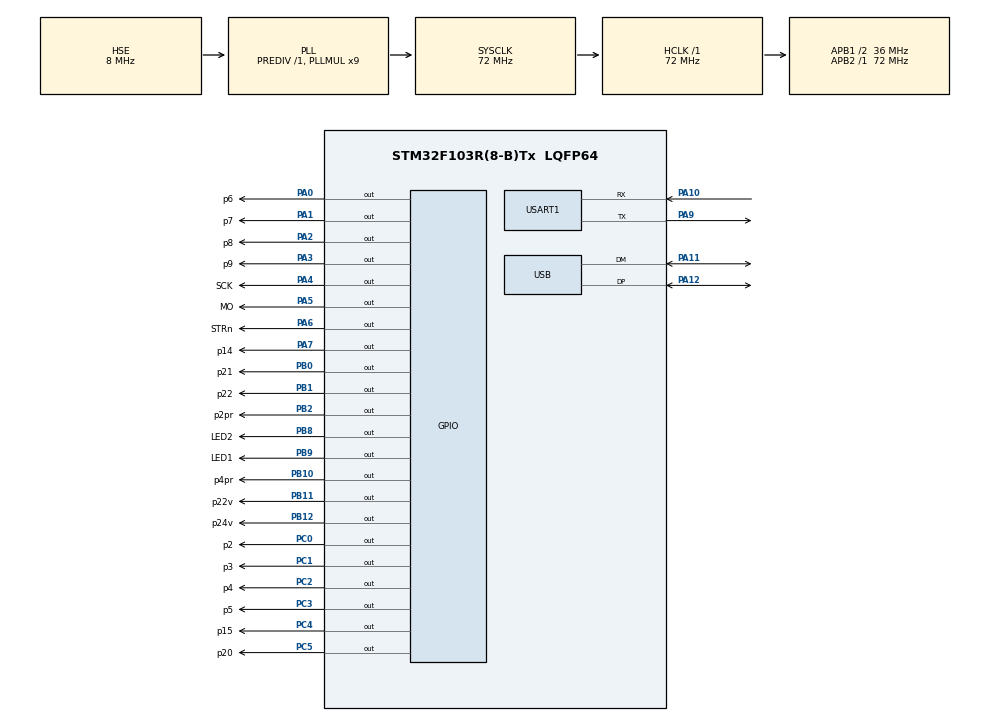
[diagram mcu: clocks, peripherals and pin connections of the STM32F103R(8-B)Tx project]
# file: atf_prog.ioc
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FREERTOS.INCLUDE_vTaskDelete=0
FREERTOS.Tasks01=Prog,0,128,StartProg,Default,NULL,Dynamic,NULL,NULL;LED,-3,128,StartLED,Default,NULL,Dynamic,NULL,NULL
Mcu.Family=STM32F1
Mcu.Name=STM32F103R(8-B)Tx
Mcu.Package=LQFP64
NVIC.PriorityGroup=NVIC_PRIORITYGROUP_4
NVIC.RCC_IRQn=true\:5\:0\:false\:true\:true\:2\:true\:true
NVIC.TIM1_UP_IRQn=true\:0\:0\:false\:false\:true\:false\:false
NVIC.TimeBase=TIM1_UP_IRQn
NVIC.TimeBaseIP=TIM1
NVIC.USART1_IRQn=true\:5\:0\:false\:true\:true\:1\:true\:true
NVIC.USB_LP_CAN1_RX0_IRQn=true\:5\:0\:false\:false\:true\:true\:false
PA0-WKUP.GPIO_Label=p6
PA0-WKUP.GPIO_ModeDefaultOutputPP=GPIO_MODE_OUTPUT_OD
PA0-WKUP.GPIO_Speed=GPIO_SPEED_FREQ_LOW
PA0-WKUP.PinState=GPIO_PIN_SET
PA0-WKUP.Signal=GPIO_Output
PA1.GPIO_Label=p7
PA1.GPIO_ModeDefaultOutputPP=GPIO_MODE_OUTPUT_OD
PA1.GPIO_Speed=GPIO_SPEED_FREQ_LOW
PA1.PinState=GPIO_PIN_SET
PA1.Signal=GPIO_Output
PA10.Mode=Asynchronous
PA10.Signal=USART1_RX
PA11.Mode=Device
PA11.Signal=USB_DM
PA12.Mode=Device
PA12.Signal=USB_DP
PA13.Mode=Serial_Wire
PA13.Signal=SYS_JTMS-SWDIO
PA14.Mode=Serial_Wire
PA14.Signal=SYS_JTCK-SWCLK
PA2.GPIO_Label=p8
PA2.GPIO_ModeDefaultOutputPP=GPIO_MODE_OUTPUT_OD
PA2.GPIO_Speed=GPIO_SPEED_FREQ_LOW
PA2.PinState=GPIO_PIN_SET
PA2.Signal=GPIO_Output
PA3.GPIO_Label=p9
PA3.GPIO_ModeDefaultOutputPP=GPIO_MODE_OUTPUT_OD
PA3.GPIO_Speed=GPIO_SPEED_FREQ_LOW
PA3.PinState=GPIO_PIN_SET
PA3.Signal=GPIO_Output
PA4.GPIO_Label=SCK
PA4.GPIO_ModeDefaultOutputPP=GPIO_MODE_OUTPUT_OD
PA4.GPIO_Speed=GPIO_SPEED_FREQ_LOW
PA4.PinState=GPIO_PIN_SET
PA4.Signal=GPIO_Output
PA5.GPIO_Label=MO
PA5.GPIO_ModeDefaultOutputPP=GPIO_MODE_OUTPUT_OD
PA5.GPIO_Speed=GPIO_SPEED_FREQ_LOW
PA5.PinState=GPIO_PIN_SET
PA5.Signal=GPIO_Output
PA6.GPIO_Label=STRn
PA6.GPIO_ModeDefaultOutputPP=GPIO_MODE_OUTPUT_OD
PA6.GPIO_Speed=GPIO_SPEED_FREQ_LOW
PA6.PinState=GPIO_PIN_SET
PA6.Signal=GPIO_Output
PA7.GPIO_Label=p14
PA7.GPIO_ModeDefaultOutputPP=GPIO_MODE_OUTPUT_OD
PA7.GPIO_Speed=GPIO_SPEED_FREQ_LOW
PA7.PinState=GPIO_PIN_SET
PA7.Signal=GPIO_Output
PA9.Mode=Asynchronous
PA9.Signal=USART1_TX
PB0.GPIO_Label=p21
PB0.GPIO_ModeDefaultOutputPP=GPIO_MODE_OUTPUT_OD
PB0.GPIO_Speed=GPIO_SPEED_FREQ_LOW
PB0.PinState=GPIO_PIN_SET
PB0.Signal=GPIO_Output
PB1.GPIO_Label=p22
PB1.GPIO_ModeDefaultOutputPP=GPIO_MODE_OUTPUT_OD
PB1.GPIO_Speed=GPIO_SPEED_FREQ_LOW
PB1.PinState=GPIO_PIN_SET
PB1.Signal=GPIO_Output
PB10.GPIO_Label=p4pr
PB10.Signal=GPIO_Output
PB11.GPIO_Label=p22v
PB11.Signal=GPIO_Output
PB12.GPIO_Label=p24v
PB12.Signal=GPIO_Output
PB2.GPIO_Label=p2pr
PB2.Signal=GPIO_Output
PB8.GPIO_Label=LED2
PB8.Signal=GPIO_Output
PB9.GPIO_Label=LED1
PB9.Signal=GPIO_Output
PC0.GPIO_Label=p2
PC0.GPIO_ModeDefaultOutputPP=GPIO_MODE_OUTPUT_OD
PC0.GPIO_Speed=GPIO_SPEED_FREQ_LOW
PC0.PinState=GPIO_PIN_SET
PC0.Signal=GPIO_Output
PC1.GPIO_Label=p3
PC1.GPIO_ModeDefaultOutputPP=GPIO_MODE_OUTPUT_OD
PC1.GPIO_Speed=GPIO_SPEED_FREQ_LOW
PC1.PinState=GPIO_PIN_SET
PC1.Signal=GPIO_Output
PC14-OSC32_IN.Mode=LSE-External-Oscillator
PC14-OSC32_IN.Signal=RCC_OSC32_IN
PC15-OSC32_OUT.Mode=LSE-External-Oscillator
PC15-OSC32_OUT.Signal=RCC_OSC32_OUT
PC2.GPIO_Label=p4
PC2.GPIO_ModeDefaultOutputPP=GPIO_MODE_OUTPUT_OD
PC2.GPIO_Speed=GPIO_SPEED_FREQ_LOW
PC2.PinState=GPIO_PIN_SET
PC2.Signal=GPIO_Output
PC3.GPIO_Label=p5
PC3.GPIO_ModeDefaultOutputPP=GPIO_MODE_OUTPUT_OD
PC3.GPIO_Speed=GPIO_SPEED_FREQ_LOW
PC3.PinState=GPIO_PIN_SET
PC3.Signal=GPIO_Output
PC4.GPIO_Label=p15
PC4.GPIO_ModeDefaultOutputPP=GPIO_MODE_OUTPUT_OD
PC4.GPIO_Speed=GPIO_SPEED_FREQ_LOW
PC4.PinState=GPIO_PIN_SET
PC4.Signal=GPIO_Output
PC5.GPIO_Label=p20
PC5.GPIO_ModeDefaultOutputPP=GPIO_MODE_OUTPUT_OD
PC5.GPIO_Speed=GPIO_SPEED_FREQ_LOW
PC5.PinState=GPIO_PIN_SET
PC5.Signal=GPIO_Output
PD0-OSC_IN.Mode=HSE-External-Oscillator
PD0-OSC_IN.Signal=RCC_OSC_IN
PD1-OSC_OUT.Mode=HSE-External-Oscillator
PD1-OSC_OUT.Signal=RCC_OSC_OUT
ProjectManager.HeapSize=0x200
ProjectManager.StackSize=0x400
ProjectManager.TargetToolchain=MDK-ARM V5
RCC.AHBFreq_Value=72000000
RCC.APB1CLKDivider=RCC_HCLK_DIV2
RCC.APB1Freq_Value=36000000
RCC.APB1TimFreq_Value=72000000
RCC.APB2Freq_Value=72000000
RCC.APB2TimFreq_Value=72000000
RCC.EnbaleCSS=true
RCC.HCLKFreq_Value=72000000
RCC.PLLMUL=RCC_PLL_MUL9
RCC.SYSCLKFreq_VALUE=72000000
RCC.SYSCLKSource=RCC_SYSCLKSOURCE_PLLCLK
RCC.USBFreq_Value=48000000
RCC.USBPrescaler=RCC_USBCLKSOURCE_PLL_DIV1_5
USART1.VirtualMode=VM_ASYNC
USB.ep0_mps=DEP0CTL_MPS_64
USB_DEVICE.CLASS_NAME_FS=CUSTOMHID
USB_DEVICE.CONFIGURATION_STRING_CUSTOMHID_FS=ATFP HID Config
USB_DEVICE.INTERFACE_STRING_CUSTOMHID_FS=ATFP HID Interface
USB_DEVICE.MANUFACTURER_STRING=andreil
USB_DEVICE.PID_CUSTOMHID_FS=7346
USB_DEVICE.PRODUCT_STRING_CUSTOMHID_FS=ATF Prog
USB_DEVICE.SERIALNUMBER_STRING_CUSTOMHID_FS=000000000057
USB_DEVICE.USBD_CUSTOMHID_OUTREPORT_BUF_SIZE=32
USB_DEVICE.USBD_CUSTOM_HID_REPORT_DESC_SIZE=32
USB_DEVICE.USBD_DEBUG_LEVEL=3
USB_DEVICE.VirtualMode=CustomHid
USB_DEVICE.VirtualModeFS=Custom_Hid_FS
VP_FREERTOS_VS_ENABLE.Mode=Enabled
VP_IWDG_VS_IWDG.Mode=IWDG_Activate
VP_SYS_VS_tim1.Mode=TIM1
VP_USB_DEVICE_VS_USB_DEVICE_CUSTOM_HID_FS.Mode=CUSTOM_HID_FS
board=atf_prog

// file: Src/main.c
/**
  ******************************************************************************
  * @file           : main.c
  * @brief          : Main program body
  ******************************************************************************
  * This notice applies to any and all portions of this file
  * that are not between comment pairs USER CODE BEGIN and
  * USER CODE END. Other portions of this file, whether
  * inserted by the user or by software development tools
  * are owned by their respective copyright owners.
  *
  * Copyright (c) 2018 STMicroelectronics International N.V.
  * All rights reserved.
  *
  * Redistribution and use in source and binary forms, with or without
  * modification, are permitted, provided that the following conditions are met:
  *
  * 1. Redistribution of source code must retain the above copyright notice,
  *    this list of conditions and the following disclaimer.
  * 2. Redistributions in binary form must reproduce the above copyright notice,
  *    this list of conditions and the following disclaimer in the documentation
  *    and/or other materials provided with the distribution.
  * 3. Neither the name of STMicroelectronics nor the names of other
  *    contributors to this software may be used to endorse or promote products
  *    derived from this software without specific written permission.
  * 4. This software, including modifications and/or derivative works of this
  *    software, must execute solely and exclusively on microcontroller or
  *    microprocessor devices manufactured by or for STMicroelectronics.
  * 5. Redistribution and use of this software other than as permitted under
  *    this license is void and will automatically terminate your rights under
  *    this license.
  *
  * THIS SOFTWARE IS PROVIDED BY STMICROELECTRONICS AND CONTRIBUTORS "AS IS"
  * AND ANY EXPRESS, IMPLIED OR STATUTORY WARRANTIES, INCLUDING, BUT NOT
  * LIMITED TO, THE IMPLIED WARRANTIES OF MERCHANTABILITY, FITNESS FOR A
  * PARTICULAR PURPOSE AND NON-INFRINGEMENT OF THIRD PARTY INTELLECTUAL PROPERTY
  * RIGHTS ARE DISCLAIMED TO THE FULLEST EXTENT PERMITTED BY LAW. IN NO EVENT
  * SHALL STMICROELECTRONICS OR CONTRIBUTORS BE LIABLE FOR ANY DIRECT, INDIRECT,
  * INCIDENTAL, SPECIAL, EXEMPLARY, OR CONSEQUENTIAL DAMAGES (INCLUDING, BUT NOT
  * LIMITED TO, PROCUREMENT OF SUBSTITUTE GOODS OR SERVICES; LOSS OF USE, DATA,
  * OR PROFITS; OR BUSINESS INTERRUPTION) HOWEVER CAUSED AND ON ANY THEORY OF
  * LIABILITY, WHETHER IN CONTRACT, STRICT LIABILITY, OR TORT (INCLUDING
  * NEGLIGENCE OR OTHERWISE) ARISING IN ANY WAY OUT OF THE USE OF THIS SOFTWARE,
  * EVEN IF ADVISED OF THE POSSIBILITY OF SUCH DAMAGE.
  *
  ******************************************************************************
  */
#include "main.h"
#include "stm32f1xx_hal.h"
#include "cmsis_os.h"
#include "usb_device.h"

/* USER CODE BEGIN Includes */
#include "gal_prog.h"
/* USER CODE END Includes */

IWDG_HandleTypeDef hiwdg;

UART_HandleTypeDef huart1;

osThreadId ProgHandle;
osThreadId LEDHandle;

/* USER CODE BEGIN PV */
/* Private variables ---------------------------------------------------------*/
GALProg_t prog;
/* USER CODE END PV */

void SystemClock_Config(void);
static void MX_GPIO_Init(void);
static void MX_IWDG_Init(void);
static void MX_USART1_UART_Init(void);
void StartProg(void const * argument);
void StartLED(void const * argument);
static void MX_NVIC_Init(void);

/* USER CODE BEGIN PFP */
/* Private function prototypes -----------------------------------------------*/

/* USER CODE END PFP */

/* USER CODE BEGIN 0 */

int fputc(int ch, FILE *f)
{
  /* Place your implementation of fputc here */
  /* e.g. write a character to the USART1 and Loop until the end of transmission */
  HAL_UART_Transmit(&huart1, (uint8_t *)&ch, 1, 0xFFFF);

  return ch;
}

/* USER CODE END 0 */

int main(void)
{

  /* MCU Configuration----------------------------------------------------------*/

  /* Reset of all peripherals, Initializes the Flash interface and the Systick. */
  HAL_Init();

  /* Configure the system clock */
  SystemClock_Config();

  /* Initialize all configured peripherals */
  MX_GPIO_Init();
  MX_IWDG_Init();
  MX_USART1_UART_Init();

  /* Initialize interrupts */
  MX_NVIC_Init();
  /* USER CODE BEGIN 2 */

	printf("ATF Programmer\n\r");

  /* USER CODE END 2 */

  /* Create the thread(s) */
  /* definition and creation of Prog */
  osThreadDef(Prog, StartProg, osPriorityNormal, 0, 128);
  ProgHandle = osThreadCreate(osThread(Prog), NULL);

  /* definition and creation of LED */
  osThreadDef(LED, StartLED, osPriorityIdle, 0, 128);
  LEDHandle = osThreadCreate(osThread(LED), NULL);

  /* Start scheduler */
  osKernelStart();

  /* We should never get here as control is now taken by the scheduler */

  /* Infinite loop */
  while (1)
  {

  }

}

void SystemClock_Config(void)
{

  RCC_OscInitTypeDef RCC_OscInitStruct;
  RCC_ClkInitTypeDef RCC_ClkInitStruct;
  RCC_PeriphCLKInitTypeDef PeriphClkInit;

    /**Initializes the CPU, AHB and APB busses clocks
    */
  RCC_OscInitStruct.OscillatorType = RCC_OSCILLATORTYPE_LSI|RCC_OSCILLATORTYPE_HSE;
  RCC_OscInitStruct.HSEState = RCC_HSE_ON;
  RCC_OscInitStruct.HSEPredivValue = RCC_HSE_PREDIV_DIV1;
  RCC_OscInitStruct.HSIState = RCC_HSI_ON;
  RCC_OscInitStruct.LSIState = RCC_LSI_ON;
  RCC_OscInitStruct.PLL.PLLState = RCC_PLL_ON;
  RCC_OscInitStruct.PLL.PLLSource = RCC_PLLSOURCE_HSE;
  RCC_OscInitStruct.PLL.PLLMUL = RCC_PLL_MUL9;
  if (HAL_RCC_OscConfig(&RCC_OscInitStruct) != HAL_OK)
  {
    _Error_Handler(__FILE__, __LINE__);
  }

    /**Initializes the CPU, AHB and APB busses clocks
    */
  RCC_ClkInitStruct.ClockType = RCC_CLOCKTYPE_HCLK|RCC_CLOCKTYPE_SYSCLK
                              |RCC_CLOCKTYPE_PCLK1|RCC_CLOCKTYPE_PCLK2;
  RCC_ClkInitStruct.SYSCLKSource = RCC_SYSCLKSOURCE_PLLCLK;
  RCC_ClkInitStruct.AHBCLKDivider = RCC_SYSCLK_DIV1;
  RCC_ClkInitStruct.APB1CLKDivider = RCC_HCLK_DIV2;
  RCC_ClkInitStruct.APB2CLKDivider = RCC_HCLK_DIV1;

  if (HAL_RCC_ClockConfig(&RCC_ClkInitStruct, FLASH_LATENCY_2) != HAL_OK)
  {
    _Error_Handler(__FILE__, __LINE__);
  }

  PeriphClkInit.PeriphClockSelection = RCC_PERIPHCLK_USB;
  PeriphClkInit.UsbClockSelection = RCC_USBCLKSOURCE_PLL_DIV1_5;
  if (HAL_RCCEx_PeriphCLKConfig(&PeriphClkInit) != HAL_OK)
  {
    _Error_Handler(__FILE__, __LINE__);
  }

    /**Enables the Clock Security System
    */
  HAL_RCC_EnableCSS();

    /**Configure the Systick interrupt time
    */
  HAL_SYSTICK_Config(HAL_RCC_GetHCLKFreq()/1000);

    /**Configure the Systick
    */
  HAL_SYSTICK_CLKSourceConfig(SYSTICK_CLKSOURCE_HCLK);

  /* SysTick_IRQn interrupt configuration */
  HAL_NVIC_SetPriority(SysTick_IRQn, 15, 0);
}

/**
  * @brief NVIC Configuration.
  * @retval None
  */
static void MX_NVIC_Init(void)
{
  /* USART1_IRQn interrupt configuration */
  HAL_NVIC_SetPriority(USART1_IRQn, 5, 0);
  HAL_NVIC_EnableIRQ(USART1_IRQn);
  /* RCC_IRQn interrupt configuration */
  HAL_NVIC_SetPriority(RCC_IRQn, 5, 0);
  HAL_NVIC_EnableIRQ(RCC_IRQn);
}

/* IWDG init function */
static void MX_IWDG_Init(void)
{

  hiwdg.Instance = IWDG;
  hiwdg.Init.Prescaler = IWDG_PRESCALER_4;
  hiwdg.Init.Reload = 4095;
  if (HAL_IWDG_Init(&hiwdg) != HAL_OK)
  {
    _Error_Handler(__FILE__, __LINE__);
  }

}

/* USART1 init function */
static void MX_USART1_UART_Init(void)
{

  huart1.Instance = USART1;
  huart1.Init.BaudRate = 115200;
  huart1.Init.WordLength = UART_WORDLENGTH_8B;
  huart1.Init.StopBits = UART_STOPBITS_1;
  huart1.Init.Parity = UART_PARITY_NONE;
  huart1.Init.Mode = UART_MODE_TX_RX;
  huart1.Init.HwFlowCtl = UART_HWCONTROL_NONE;
  huart1.Init.OverSampling = UART_OVERSAMPLING_16;
  if (HAL_UART_Init(&huart1) != HAL_OK)
  {
    _Error_Handler(__FILE__, __LINE__);
  }

}

/** Configure pins as
        * Analog
        * Input
        * Output
        * EVENT_OUT
        * EXTI
        * Free pins are configured automatically as Analog (this feature is enabled through
        * the Code Generation settings)
*/
static void MX_GPIO_Init(void)
{

  GPIO_InitTypeDef GPIO_InitStruct;

  /* GPIO Ports Clock Enable */
  __HAL_RCC_GPIOC_CLK_ENABLE();
  __HAL_RCC_GPIOD_CLK_ENABLE();
  __HAL_RCC_GPIOA_CLK_ENABLE();
  __HAL_RCC_GPIOB_CLK_ENABLE();

  /*Configure GPIO pin Output Level */
  HAL_GPIO_WritePin(GPIOC, p2_Pin|p3_Pin|p4_Pin|p5_Pin
                          |p15_Pin|p20_Pin, GPIO_PIN_SET);

  /*Configure GPIO pin Output Level */
  HAL_GPIO_WritePin(GPIOA, p6_Pin|p7_Pin|p8_Pin|p9_Pin
                          |SCK_Pin|MO_Pin|STRn_Pin|p14_Pin, GPIO_PIN_SET);

  /*Configure GPIO pin Output Level */
  HAL_GPIO_WritePin(GPIOB, p21_Pin|p22_Pin, GPIO_PIN_SET);

  /*Configure GPIO pin Output Level */
  HAL_GPIO_WritePin(GPIOB, p2pr_Pin|p4pr_Pin|p22v_Pin|p24v_Pin
                          |LED2_Pin|LED1_Pin, GPIO_PIN_RESET);

  /*Configure GPIO pins : PC13 PC6 PC7 PC8
                           PC9 PC10 PC11 PC12 */
  GPIO_InitStruct.Pin = GPIO_PIN_13|GPIO_PIN_6|GPIO_PIN_7|GPIO_PIN_8
                          |GPIO_PIN_9|GPIO_PIN_10|GPIO_PIN_11|GPIO_PIN_12;
  GPIO_InitStruct.Mode = GPIO_MODE_ANALOG;
  HAL_GPIO_Init(GPIOC, &GPIO_InitStruct);

  /*Configure GPIO pins : p2_Pin p3_Pin p4_Pin p5_Pin
                           p15_Pin p20_Pin */
  GPIO_InitStruct.Pin = p2_Pin|p3_Pin|p4_Pin|p5_Pin
                          |p15_Pin|p20_Pin;
  GPIO_InitStruct.Mode = GPIO_MODE_OUTPUT_OD;
  GPIO_InitStruct.Speed = GPIO_SPEED_FREQ_LOW;
  HAL_GPIO_Init(GPIOC, &GPIO_InitStruct);

  /*Configure GPIO pins : p6_Pin p7_Pin p8_Pin p9_Pin
                           SCK_Pin MO_Pin STRn_Pin p14_Pin */
  GPIO_InitStruct.Pin = p6_Pin|p7_Pin|p8_Pin|p9_Pin
                          |SCK_Pin|MO_Pin|STRn_Pin|p14_Pin;
  GPIO_InitStruct.Mode = GPIO_MODE_OUTPUT_OD;
  GPIO_InitStruct.Speed = GPIO_SPEED_FREQ_LOW;
  HAL_GPIO_Init(GPIOA, &GPIO_InitStruct);

  /*Configure GPIO pins : p21_Pin p22_Pin */
  GPIO_InitStruct.Pin = p21_Pin|p22_Pin;
  GPIO_InitStruct.Mode = GPIO_MODE_OUTPUT_OD;
  GPIO_InitStruct.Speed = GPIO_SPEED_FREQ_LOW;
  HAL_GPIO_Init(GPIOB, &GPIO_InitStruct);

  /*Configure GPIO pins : p2pr_Pin p4pr_Pin p22v_Pin p24v_Pin
                           LED2_Pin LED1_Pin */
  GPIO_InitStruct.Pin = p2pr_Pin|p4pr_Pin|p22v_Pin|p24v_Pin
                          |LED2_Pin|LED1_Pin;
  GPIO_InitStruct.Mode = GPIO_MODE_OUTPUT_PP;
  GPIO_InitStruct.Speed = GPIO_SPEED_FREQ_LOW;
  HAL_GPIO_Init(GPIOB, &GPIO_InitStruct);

  /*Configure GPIO pins : PB13 PB14 PB15 PB3
                           PB4 PB5 PB6 PB7 */
  GPIO_InitStruct.Pin = GPIO_PIN_13|GPIO_PIN_14|GPIO_PIN_15|GPIO_PIN_3
                          |GPIO_PIN_4|GPIO_PIN_5|GPIO_PIN_6|GPIO_PIN_7;
  GPIO_InitStruct.Mode = GPIO_MODE_ANALOG;
  HAL_GPIO_Init(GPIOB, &GPIO_InitStruct);

  /*Configure GPIO pins : PA8 PA15 */
  GPIO_InitStruct.Pin = GPIO_PIN_8|GPIO_PIN_15;
  GPIO_InitStruct.Mode = GPIO_MODE_ANALOG;
  HAL_GPIO_Init(GPIOA, &GPIO_InitStruct);

  /*Configure GPIO pin : PD2 */
  GPIO_InitStruct.Pin = GPIO_PIN_2;
  GPIO_InitStruct.Mode = GPIO_MODE_ANALOG;
  HAL_GPIO_Init(GPIOD, &GPIO_InitStruct);

}

/* StartProg function */
void StartProg(void const * argument)
{
  /* init code for USB_DEVICE */
  MX_USB_DEVICE_Init();

  /* USER CODE BEGIN 5 */
	prog_init(&prog);

  for(;;)
  {
		if (prog_proc(&prog))
			osDelay(1);
  }
  /* USER CODE END 5 */
}

/* StartLED function */
void StartLED(void const * argument)
{
  /* USER CODE BEGIN StartLED */
	int counter = 0;
	HAL_GPIO_WritePin(LED2_GPIO_Port, LED2_Pin, GPIO_PIN_SET);
  for(;;)
  {
		if (counter++ == 500)
		{
			HAL_GPIO_TogglePin(LED1_GPIO_Port, LED1_Pin);
			counter = 0;
		}
    osDelay(1);
		HAL_IWDG_Refresh(&hiwdg);
  }
  /* USER CODE END StartLED */
}

void HAL_TIM_PeriodElapsedCallback(TIM_HandleTypeDef *htim)
{
  if (htim->Instance == TIM1) {
    HAL_IncTick();
  }
}

void _Error_Handler(char *file, int line)
{
  while(1)
  {
  }
}

/************************ (C) COPYRIGHT STMicroelectronics *****END OF FILE****/
